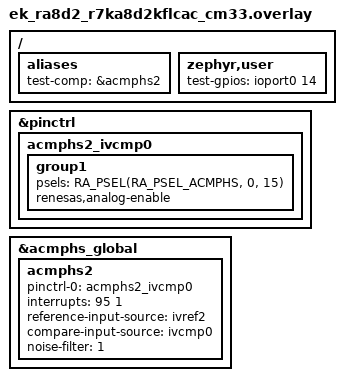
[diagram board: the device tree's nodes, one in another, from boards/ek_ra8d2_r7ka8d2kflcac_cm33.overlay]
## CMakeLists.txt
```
# Copyright (c) 2024 Nordic Semiconductor
# SPDX-License-Identifier: Apache-2.0

cmake_minimum_required(VERSION 3.28.0)
find_package(Zephyr REQUIRED HINTS $ENV{ZEPHYR_BASE})
project(comparator_gpio_loopback)

target_sources(app PRIVATE src/test.c)
```

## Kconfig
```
# Copyright (c) 2025 Renesas Electronics Corporation
# SPDX-License-Identifier: Apache-2.0

mainmenu "GPIO_loopback test additional options"

source "Kconfig.zephyr"

ZEPHYR_USER := zephyr,user

config DAC_REFERENCE_SOURCE
	bool
	default y if $(dt_node_has_prop,/$(ZEPHYR_USER),dac)
	select DAC
```

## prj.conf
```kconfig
# Copyright (c) 2024 Nordic Semiconductor ASA
# SPDX-License-Identifier: Apache-2.0

CONFIG_ZTEST=y
CONFIG_GPIO=y
CONFIG_COMPARATOR=y
```

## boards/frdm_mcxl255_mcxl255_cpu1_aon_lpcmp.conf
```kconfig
# Copyright 2026 NXP
# SPDX-License-Identifier: Apache-2.0

CONFIG_BOOT_BANNER=n
CONFIG_ZTEST_VERBOSE_OUTPUT=n
CONFIG_ZTEST_SUMMARY=y
CONFIG_HEAP_MEM_POOL_SIZE=64
CONFIG_THREAD_STACK_INFO=n
CONFIG_CBPRINTF_NANO=y
CONFIG_MAIN_STACK_SIZE=512
CONFIG_ZTEST_STACK_SIZE=512
CONFIG_IDLE_STACK_SIZE=256
CONFIG_ISR_STACK_SIZE=512
CONFIG_SYSTEM_WORKQUEUE_STACK_SIZE=256
```

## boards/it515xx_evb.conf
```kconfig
# Copyright (c) 2025 ITE Technology Corporation
# SPDX-License-Identifier: Apache-2.0

CONFIG_ADC=y
```

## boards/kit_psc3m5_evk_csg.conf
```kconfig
# SPDX-FileCopyrightText: Copyright (c) 2026 Infineon Technologies AG,
# SPDX-FileCopyrightText: or an affiliate of Infineon Technologies AG. All rights reserved.
#
# SPDX-License-Identifier: Apache-2.0
#
# Companion conf for boards/kit_psc3m5_evk_csg.overlay (FILE_SUFFIX=csg).
# Pulls in the HPPASS MFD and CSG DAC needed by the CSG comparator.

CONFIG_MFD=y
CONFIG_DAC=y
```

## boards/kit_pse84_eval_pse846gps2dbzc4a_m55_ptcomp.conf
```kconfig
# Copyright (c) 2026 Infineon Technologies AG,
# or an affiliate of Infineon Technologies AG.
#
# SPDX-License-Identifier: Apache-2.0

CONFIG_REGULATOR=y
```

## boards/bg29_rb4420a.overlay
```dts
/*
 * Copyright (c) 2025 Silicon Laboratories Inc.
 *
 * SPDX-License-Identifier: Apache-2.0
 */

#include <zephyr/dt-bindings/gpio/gpio.h>
#include <zephyr/dt-bindings/comparator/silabs-acmp.h>
#include <zephyr/dt-bindings/pinctrl/silabs/xg29-pinctrl.h>

/ {
	aliases {
		test-comp = &acmp0;
	};

	zephyr,user {
		test-gpios = <&gpioc 5 GPIO_ACTIVE_HIGH>;
	};
};

&pinctrl {
	acmp0_default: acmp0_default {
		group0 {
			silabs,analog-bus = <ABUS_CDODD0_ACMP0>;
		};
	};
};

&acmp0 {
	pinctrl-0 = <&acmp0_default>;
	pinctrl-names = "default";

	bias = <0>;
	hysteresis-mode = "disabled";
	accuracy-mode = "high";
	input-range = "full";
	input-positive = <ACMP_INPUT_PC5>;
	input-negative = <ACMP_INPUT_VREFDIV1V25>;
	vref-divider = <63>;
	status = "okay";
};
```

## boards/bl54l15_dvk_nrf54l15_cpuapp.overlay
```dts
/*
 * Copyright (c) 2024 Nordic Semiconductor
 * Copyright (c) 2025 Ezurio LLC
 *
 * SPDX-License-Identifier: Apache-2.0
 */

#include <zephyr/dt-bindings/gpio/gpio.h>

/*
 * P1.10 looped back to P1.11
 */

/ {
	aliases {
		test-comp = &comp;
	};

	zephyr,user {
		test-gpios = <&gpio1 10 GPIO_ACTIVE_HIGH>;
	};
};

&gpio1 {
	status = "okay";
};
```

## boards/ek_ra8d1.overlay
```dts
/*
 * Copyright (c) 2025 Renesas Electronics Corporation
 * SPDX-License-Identifier: Apache-2.0
 */

#include <zephyr/dt-bindings/gpio/gpio.h>

/ {
	aliases {
		test-comp = &acmphs0;
	};

	zephyr,user {
		test-gpios = <&ioport6 0 GPIO_ACTIVE_HIGH>;
	};
};

&acmphs_global {
	status = "okay";

	acmphs0 {
		pinctrl-0 = <&acmphs_ivref0 &acmphs0_ivcmp0>;
		pinctrl-names = "default";
		interrupts = <90 12>;
		interrupt-names = "hs";
		reference-input-source = "ivref0";
		compare-input-source = "ivcmp0";
		noise-filter = <1>;
		status = "okay";
	};
};
```

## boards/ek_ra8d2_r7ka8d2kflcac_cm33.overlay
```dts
/*
 * Copyright (c) 2026 Renesas Electronics Corporation
 * SPDX-License-Identifier: Apache-2.0
 */

#include <zephyr/dt-bindings/gpio/gpio.h>

/ {
	aliases {
		test-comp = &acmphs2;
	};

	zephyr,user {
		test-gpios = <&ioport0 14 GPIO_ACTIVE_HIGH>;
	};
};

&pinctrl {
	acmphs2_ivcmp0: acmphs2_ivcmp0 {
		group1 {
			/* CH2 IVCMP0 */
			psels = <RA_PSEL(RA_PSEL_ACMPHS, 0, 15)>;
			renesas,analog-enable;
		};
	};
};

&acmphs_global {
	status = "okay";

	acmphs2 {
		pinctrl-0 = <&acmphs2_ivcmp0>;
		pinctrl-names = "default";
		interrupts = <95 1>;
		interrupt-names = "hs";
		reference-input-source = "ivref2";
		compare-input-source = "ivcmp0";
		noise-filter = <1>;
		status = "okay";
	};
};
```

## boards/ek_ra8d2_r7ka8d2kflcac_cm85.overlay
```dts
/*
 * Copyright (c) 2025 Renesas Electronics Corporation
 * SPDX-License-Identifier: Apache-2.0
 */

#include <zephyr/dt-bindings/gpio/gpio.h>

/ {
	aliases {
		test-comp = &acmphs2;
	};

	zephyr,user {
		test-gpios = <&ioport0 14 GPIO_ACTIVE_HIGH>;
	};
};

&pinctrl {
	acmphs2_ivcmp0: acmphs2_ivcmp0 {
		group1 {
			/* CH2 IVCMP0 */
			psels = <RA_PSEL(RA_PSEL_ACMPHS, 0, 15)>;
			renesas,analog-enable;
		};
	};
};

&acmphs_global {
	status = "okay";

	acmphs2 {
		pinctrl-0 = <&acmphs2_ivcmp0>;
		pinctrl-names = "default";
		interrupts = <95 1>;
		interrupt-names = "hs";
		reference-input-source = "ivref2";
		compare-input-source = "ivcmp0";
		noise-filter = <1>;
		status = "okay";
	};
};
```

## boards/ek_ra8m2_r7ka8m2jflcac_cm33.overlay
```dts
/*
 * Copyright (c) 2026 Renesas Electronics Corporation
 * SPDX-License-Identifier: Apache-2.0
 */

#include <zephyr/dt-bindings/gpio/gpio.h>

/ {
	aliases {
		test-comp = &acmphs0;
	};

	zephyr,user {
		test-gpios = <&ioport0 7 GPIO_ACTIVE_HIGH>;
	};
};

&pinctrl {
	acmphs0_ivcmp0: acmphs0_ivcmp0 {
		group1 {
			/* CH0 IVCMP3 */
			psels = <RA_PSEL(RA_PSEL_ACMPHS, 0, 1)>;
			renesas,analog-enable;
		};
	};
};

&acmphs_global {
	status = "okay";

	acmphs0 {
		pinctrl-0 = <&acmphs0_ivcmp0>;
		pinctrl-names = "default";
		interrupts = <95 1>;
		interrupt-names = "hs";
		reference-input-source = "ivref2";
		compare-input-source = "ivcmp3";
		noise-filter = <1>;
		status = "okay";
	};
};
```

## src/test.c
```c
/*
 * Copyright (c) 2024 Nordic Semiconductor ASA
 * Copyright 2026 NXP
 *
 * SPDX-License-Identifier: Apache-2.0
 */

#include <zephyr/drivers/comparator.h>
#include <zephyr/drivers/gpio.h>
#include <zephyr/kernel.h>
#include <zephyr/ztest.h>

static const struct device *test_dev = DEVICE_DT_GET(DT_ALIAS(test_comp));
static const struct gpio_dt_spec test_pin = GPIO_DT_SPEC_GET(DT_PATH(zephyr_user), test_gpios);
static K_SEM_DEFINE(test_sem, 0, 1);

static void test_callback(const struct device *dev, void *user_data)
{
	zassert_equal(&test_sem, user_data);
	k_sem_give(&test_sem);
}

static void *test_setup(void)
{
	zassert_ok(gpio_pin_configure_dt(&test_pin, GPIO_OUTPUT_INACTIVE));
	return NULL;
}

static void test_before(void *f)
{
	ARG_UNUSED(f);

	k_sem_reset(&test_sem);
	zassert_ok(gpio_pin_set_dt(&test_pin, 0));
	k_msleep(1);
	zassert_ok(comparator_set_trigger(test_dev, COMPARATOR_TRIGGER_NONE));
	zassert_ok(comparator_set_trigger_callback(test_dev, NULL, NULL));
	zassert_between_inclusive(comparator_trigger_is_pending(test_dev), 0, 1);
}

ZTEST_SUITE(comparator_gpio_loopback, NULL, test_setup, test_before, NULL, NULL);

ZTEST(comparator_gpio_loopback, test_get_output)
{
	int rc = comparator_get_output(test_dev);

	if (rc == -ENOTSUP) {
		/* Some comparator IPs only latch edge-cross events and have no
		 * register reflecting the instantaneous comparison result.
		 */
		ztest_test_skip();
	}

	zassert_equal(rc, 0);
	k_msleep(1);
	zassert_ok(gpio_pin_set_dt(&test_pin, 1));
	k_msleep(1);
	zassert_equal(comparator_get_output(test_dev), 1);
	k_msleep(1);
	zassert_ok(gpio_pin_set_dt(&test_pin, 0));
	k_msleep(1);
	zassert_equal(comparator_get_output(test_dev), 0);
}

ZTEST(comparator_gpio_loopback, test_no_trigger_no_pending)
{
	zassert_ok(gpio_pin_set_dt(&test_pin, 1));
	k_msleep(1);
	zassert_equal(comparator_trigger_is_pending(test_dev), 0);
	zassert_ok(gpio_pin_set_dt(&test_pin, 0));
	k_msleep(1);
	zassert_equal(comparator_trigger_is_pending(test_dev), 0);
}

ZTEST(comparator_gpio_loopback, test_trigger_rising_edge_pending)
{
	zassert_ok(comparator_set_trigger(test_dev, COMPARATOR_TRIGGER_RISING_EDGE));
	k_msleep(1);
	zassert_equal(comparator_trigger_is_pending(test_dev), 0);
	zassert_ok(gpio_pin_set_dt(&test_pin, 1));
	k_msleep(1);
	zassert_equal(comparator_trigger_is_pending(test_dev), 1);
	zassert_equal(comparator_trigger_is_pending(test_dev), 0);
	zassert_ok(gpio_pin_set_dt(&test_pin, 0));
	k_msleep(1);
	zassert_equal(comparator_trigger_is_pending(test_dev), 0);
}

ZTEST(comparator_gpio_loopback, test_trigger_falling_edge_pending)
{
	zassert_ok(comparator_set_trigger(test_dev, COMPARATOR_TRIGGER_FALLING_EDGE));
	k_msleep(1);
	zassert_equal(comparator_trigger_is_pending(test_dev), 0);
	zassert_ok(gpio_pin_set_dt(&test_pin, 1));
	k_msleep(1);
	zassert_equal(comparator_trigger_is_pending(test_dev), 0);
	zassert_ok(gpio_pin_set_dt(&test_pin, 0));
	k_msleep(1);
	zassert_equal(comparator_trigger_is_pending(test_dev), 1);
	zassert_equal(comparator_trigger_is_pending(test_dev), 0);
}

ZTEST(comparator_gpio_loopback, test_trigger_both_edges_pending)
{
	int rc = comparator_set_trigger(test_dev, COMPARATOR_TRIGGER_BOTH_EDGES);

	if (rc == -ENOTSUP) {
		/* If driver explicitly doesn't support BOTH — skip the test. */
		ztest_test_skip();
	}

	zassert_ok(rc);
	k_msleep(1);
	zassert_equal(comparator_trigger_is_pending(test_dev), 0);
	zassert_ok(gpio_pin_set_dt(&test_pin, 1));
	k_msleep(1);
	zassert_equal(comparator_trigger_is_pending(test_dev), 1);
	zassert_equal(comparator_trigger_is_pending(test_dev), 0);
	zassert_ok(gpio_pin_set_dt(&test_pin, 0));
	k_msleep(1);
	zassert_equal(comparator_trigger_is_pending(test_dev), 1);
	zassert_equal(comparator_trigger_is_pending(test_dev), 0);
}

ZTEST(comparator_gpio_loopback, test_trigger_callback)
{
	zassert_ok(comparator_set_trigger_callback(test_dev, test_callback, &test_sem));
	k_msleep(1);
	zassert_equal(k_sem_take(&test_sem, K_NO_WAIT), -EBUSY);
	zassert_ok(comparator_set_trigger(test_dev, COMPARATOR_TRIGGER_RISING_EDGE));
	k_msleep(1);
	zassert_equal(k_sem_take(&test_sem, K_NO_WAIT), -EBUSY);
	zassert_ok(gpio_pin_set_dt(&test_pin, 1));
	k_msleep(1);
	zassert_ok(k_sem_take(&test_sem, K_NO_WAIT));
	zassert_equal(comparator_trigger_is_pending(test_dev), 0);
}
```
